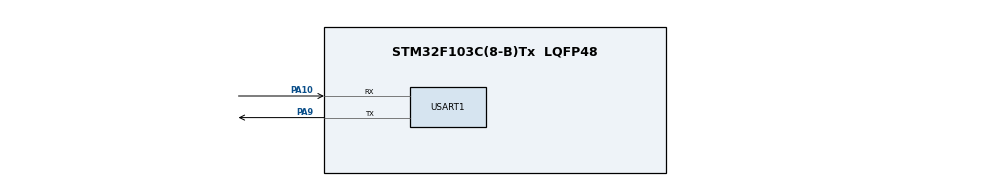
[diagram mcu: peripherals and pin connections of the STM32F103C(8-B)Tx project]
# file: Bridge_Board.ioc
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Mcu.Family=STM32F1
Mcu.Name=STM32F103C(8-B)Tx
Mcu.Package=LQFP48
NVIC.PriorityGroup=NVIC_PRIORITYGROUP_4
NVIC.USART1_IRQn=true\:0\:0\:false\:false\:true\:true\:true\:true
PA10.Mode=Asynchronous
PA10.Signal=USART1_RX
PA9.Mode=Asynchronous
PA9.Signal=USART1_TX
ProjectManager.HeapSize=0x200
ProjectManager.StackSize=0x400
ProjectManager.TargetToolchain=STM32CubeIDE
RCC.APB1Freq_Value=8000000
RCC.APB2Freq_Value=8000000
USART1.VirtualMode=VM_ASYNC
VP_SYS_VS_ND.Mode=No_Debug
board=custom

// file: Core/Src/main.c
/* USER CODE BEGIN Header */
/**
  ******************************************************************************
  * @file           : main.c
  * @brief          : Main program body
  ******************************************************************************
  * @attention
  *
  * Copyright (c) 2026 STMicroelectronics.
  * All rights reserved.
  *
  * This software is licensed under terms that can be found in the LICENSE file
  * in the root directory of this software component.
  * If no LICENSE file comes with this software, it is provided AS-IS.
  *
  ******************************************************************************
  */
/* USER CODE END Header */
#include "main.h"

UART_HandleTypeDef huart1;

/* USER CODE BEGIN PV */
uint8_t rx_char_board2; // متغیر ذخیره کاراکتر دریافتی در برد دوم
uint8_t rx_buffer[32];  // بافر برای ذخیره رشته دستور کامل
uint8_t rx_index = 0;
/* USER CODE END PV */

void SystemClock_Config(void);
static void MX_GPIO_Init(void);
static void MX_USART1_UART_Init(void);

int main(void)
{

  /* MCU Configuration--------------------------------------------------------*/

  /* Reset of all peripherals, Initializes the Flash interface and the Systick. */
  HAL_Init();

  /* Configure the system clock */
  SystemClock_Config();

  /* Initialize all configured peripherals */
  MX_GPIO_Init();
  MX_USART1_UART_Init();
  /* USER CODE BEGIN 2 */
  HAL_UART_Receive_IT(&huart1, &rx_char_board2, 1);

  /* USER CODE END 2 */

  /* Infinite loop */
  while (1)
  {

  }
}

void SystemClock_Config(void)
{
  RCC_OscInitTypeDef RCC_OscInitStruct = {0};
  RCC_ClkInitTypeDef RCC_ClkInitStruct = {0};

  /** Initializes the RCC Oscillators according to the specified parameters
  * in the RCC_OscInitTypeDef structure.
  */
  RCC_OscInitStruct.OscillatorType = RCC_OSCILLATORTYPE_HSI;
  RCC_OscInitStruct.HSIState = RCC_HSI_ON;
  RCC_OscInitStruct.HSICalibrationValue = RCC_HSICALIBRATION_DEFAULT;
  RCC_OscInitStruct.PLL.PLLState = RCC_PLL_NONE;
  if (HAL_RCC_OscConfig(&RCC_OscInitStruct) != HAL_OK)
  {
    Error_Handler();
  }

  /** Initializes the CPU, AHB and APB buses clocks
  */
  RCC_ClkInitStruct.ClockType = RCC_CLOCKTYPE_HCLK|RCC_CLOCKTYPE_SYSCLK
                              |RCC_CLOCKTYPE_PCLK1|RCC_CLOCKTYPE_PCLK2;
  RCC_ClkInitStruct.SYSCLKSource = RCC_SYSCLKSOURCE_HSI;
  RCC_ClkInitStruct.AHBCLKDivider = RCC_SYSCLK_DIV1;
  RCC_ClkInitStruct.APB1CLKDivider = RCC_HCLK_DIV1;
  RCC_ClkInitStruct.APB2CLKDivider = RCC_HCLK_DIV1;

  if (HAL_RCC_ClockConfig(&RCC_ClkInitStruct, FLASH_LATENCY_0) != HAL_OK)
  {
    Error_Handler();
  }
}

static void MX_USART1_UART_Init(void)
{

  huart1.Instance = USART1;
  huart1.Init.BaudRate = 115200;
  huart1.Init.WordLength = UART_WORDLENGTH_8B;
  huart1.Init.StopBits = UART_STOPBITS_1;
  huart1.Init.Parity = UART_PARITY_NONE;
  huart1.Init.Mode = UART_MODE_TX_RX;
  huart1.Init.HwFlowCtl = UART_HWCONTROL_NONE;
  huart1.Init.OverSampling = UART_OVERSAMPLING_16;
  if (HAL_UART_Init(&huart1) != HAL_OK)
  {
    Error_Handler();
  }

}

static void MX_GPIO_Init(void)
{

  /* GPIO Ports Clock Enable */
  __HAL_RCC_GPIOA_CLK_ENABLE();

}

/* USER CODE BEGIN 4 */
/* USER CODE BEGIN 4 */
void HAL_UART_RxCpltCallback(UART_HandleTypeDef *huart) {
    if (huart->Instance == USART1) {

        // ذخیره کاراکتر در بافر تا زمانی که پیام تمام شود
        if (rx_char_board2 != '\r' && rx_char_board2 != '\n' && rx_index < 31) {
            rx_buffer[rx_index++] = rx_char_board2;
        }
        else if (rx_index > 0) {
            rx_buffer[rx_index] = '\0'; // پایان دادن به رشته پيام

            // نمونه پاسخ: اگر پیام خاصی آمد یا برای هر پیامی یک تاییدیه بفرستد
            // نمایش روی ترمینال مجازی ۲ و فرستادن به برد ۱
            char response_msg[64];
            sprintf(response_msg, "\r\n[Board2]: Received your message!\r\n");

            // ارسال پاسخ به برد اول (و همزمان ترمینال ۲ آن را نشان می‌دهد)
            HAL_UART_Transmit(&huart1, (uint8_t*)response_msg, strlen(response_msg), HAL_MAX_DELAY);

            // صفر کردن اندکس برای پیام بعدی
            rx_index = 0;
        }

        // فعال‌سازی مجدد اینترپت برای کاراکتر بعدی
        HAL_UART_Receive_IT(&huart1, &rx_char_board2, 1);
    }
}
/* USER CODE END 4 */
/* USER CODE END 4 */

void Error_Handler(void)
{
  __disable_irq();
  while (1)
  {
  }
}
